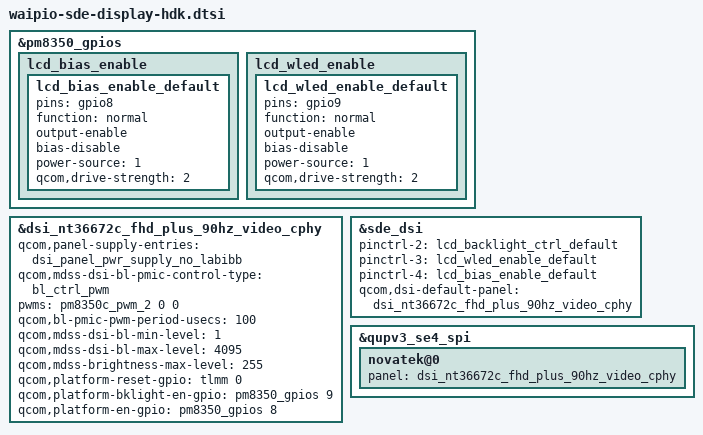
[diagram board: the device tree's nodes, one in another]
#include "waipio-sde-display.dtsi"

&pm8350_gpios {
	lcd_bias_enable {
		lcd_bias_enable_default: lcd_bias_enable_default {
			pins = "gpio8";
			function = "normal";
			output-enable;
			bias-disable;
			power-source = <1>;       /* 1.8V */
			qcom,drive-strength = <2>;
		};
	};

	lcd_wled_enable {
		lcd_wled_enable_default: lcd_wled_enable_default {
			pins = "gpio9";
			function = "normal";
			output-enable;
			bias-disable;
			power-source = <1>;       /* 1.8V */
			qcom,drive-strength = <2>;
		};
	};
};

&dsi_nt36672c_fhd_plus_90hz_video_cphy {
	qcom,panel-supply-entries = <&dsi_panel_pwr_supply_no_labibb>;
	qcom,mdss-dsi-bl-pmic-control-type = "bl_ctrl_pwm";
	pwms = <&pm8350c_pwm_2 0 0>;
	qcom,bl-pmic-pwm-period-usecs = <100>;
	qcom,mdss-dsi-bl-min-level = <1>;
	qcom,mdss-dsi-bl-max-level = <4095>;
	qcom,mdss-brightness-max-level = <255>;
	qcom,platform-reset-gpio = <&tlmm 0 0>;
	qcom,platform-bklight-en-gpio = <&pm8350_gpios 9 0>;
	qcom,platform-en-gpio = <&pm8350_gpios 8 0>;
};

&sde_dsi {
	pinctrl-names = "panel_active", "panel_suspend", "pwm_pin", "lcd_wled", "lcd_bias";
	pinctrl-2 = <&lcd_backlight_ctrl_default>;
	pinctrl-3 = <&lcd_wled_enable_default>;
	pinctrl-4 = <&lcd_bias_enable_default>;
	qcom,dsi-default-panel = <&dsi_nt36672c_fhd_plus_90hz_video_cphy>;
};

&qupv3_se4_spi {
	novatek@0 {
		panel = <&dsi_nt36672c_fhd_plus_90hz_video_cphy>;
	};
};
